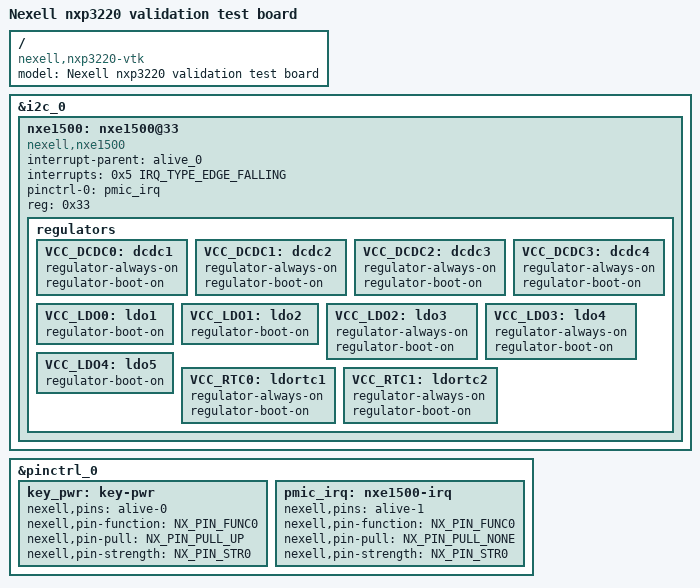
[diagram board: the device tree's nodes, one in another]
// SPDX-License-Identifier: (GPL-2.0+ OR MIT)
/*
 * Copyright (C) 2018  Nexell Co., Ltd.
 * Author: JungHyun, Kim <jhkim@nexell.co.kr>
 */

/dts-v1/;
#include <dt-bindings/gpio/gpio.h>
#include <dt-bindings/input/input.h>
#include "nxp3220-vtk-common.dtsi"

#define PMIC_PDATA_INIT(_id, _rname, _minuv,		\
                        _maxuv, _init_uv, _init_enable,	\
                        _set_init_uV, _slp_slots)	\
                regulator-name = _rname;                \
                regulator-min-microvolt = <_minuv>;     \
                regulator-max-microvolt = <_maxuv>;     \
                nx,id = <_id>;                          \
                nx,init_enable = <_init_enable>;        \
                nx,init_uV = <_init_uv>;                \
                nx,set_init_uV = <_set_init_uV>;        \
                nx,sleep_slots = <_slp_slots>;

/ {
	model = "Nexell nxp3220 validation test board";
	compatible = "nexell,nxp3220-vtk", "nexell,nxp3220";
};

&i2c_0 {
	status = "okay";
	#address-cells = <1>;
	#size-cells = <0>;

	nxe1500: nxe1500@33 {
		compatible = "nexell,nxe1500";
		interrupt-parent = <&alive_0>;
		interrupts = <0x5 IRQ_TYPE_EDGE_FALLING>;
		pinctrl-names = "default";
		pinctrl-0 = <&pmic_irq>;
		reg = <0x33>;

		regulators {
			VCC_DCDC0: dcdc1 {
					PMIC_PDATA_INIT( 0,
					"nxe1500_dcdc1",
					1000000, 1200000,
					1100000, 1, 0, 0x4)
					regulator-always-on;
					regulator-boot-on;
				};

			VCC_DCDC1: dcdc2 {
					PMIC_PDATA_INIT( 1,
					"nxe1500_dcdc2",
					975000, 1000000,
					1000000, 1, 0, 0x4)
					regulator-always-on;
					regulator-boot-on;
				};

			VCC_DCDC2: dcdc3 {
					PMIC_PDATA_INIT( 2,
					"nxe1500_dcdc3",
					1500000, 1500000,
					1500000, 1, 0, 0xF)
					regulator-always-on;
					regulator-boot-on;
				};

			VCC_DCDC3: dcdc4 {
					PMIC_PDATA_INIT( 3,
					"nxe1500_dcdc4",
					1500000, 1500000,
					1500000, 1, 0, 0xF)
					regulator-always-on;
					regulator-boot-on;
				};

			VCC_LDO0: ldo1 {
					PMIC_PDATA_INIT( 5,
					"nxe1500_ldo1",
					3300000, 3300000,
					3300000, 1, 0, 0xF)
					regulator-boot-on;
				};

			VCC_LDO1: ldo2 {
					PMIC_PDATA_INIT( 6,
					"nxe1500_ldo2",
					1800000, 1800000,
					1800000, 1, 0, 0x3)
					regulator-boot-on;
				};

			VCC_LDO2: ldo3 { PMIC_PDATA_INIT( 7,
					"nxe1500_ldo3",
					3300000, 3300000,
					3300000, 1, 0, 0x2)
					regulator-always-on;
					regulator-boot-on;
				};

			VCC_LDO3: ldo4 {
					PMIC_PDATA_INIT( 8,
					"nxe1500_ldo4",
					1500000, 1500000,
					1500000, 1, 0, 0x3)
					regulator-always-on;
					regulator-boot-on;
				};

			VCC_LDO4: ldo5 {
					PMIC_PDATA_INIT( 9,
					"nxe1500_ldo5",
					1000000, 1000000,
					1000000, 1, 0, 0x4)
					regulator-boot-on;
				};

			VCC_RTC0: ldortc1 {
					PMIC_PDATA_INIT(15,
					"nxe1500_rtc1",
					1700000, 3500000,
					1800000, 1, 1, 0xF)
					regulator-always-on;
					regulator-boot-on;
				};

			VCC_RTC1: ldortc2 {
					PMIC_PDATA_INIT(16,
					"nxe1500_rtc2",
					1000000, 3500000,
					1000000, 1, 1, 0xF)
					regulator-always-on;
					regulator-boot-on;
				};

		}; /* regulators */
	}; /* nxe1500@33 */
}; /* &i2c_0 */

&pinctrl_0 {
	key_pwr: key-pwr {
		nexell,pins = "alive-0";
		nexell,pin-function = <NX_PIN_FUNC0>;
		nexell,pin-pull = <NX_PIN_PULL_UP>;
		nexell,pin-strength = <NX_PIN_STR0>;
	};

	pmic_irq: nxe1500-irq {
		nexell,pins = "alive-1";
		nexell,pin-function = <NX_PIN_FUNC0>;
		nexell,pin-pull = <NX_PIN_PULL_NONE>;
		nexell,pin-strength = <NX_PIN_STR0>;
	};
};
